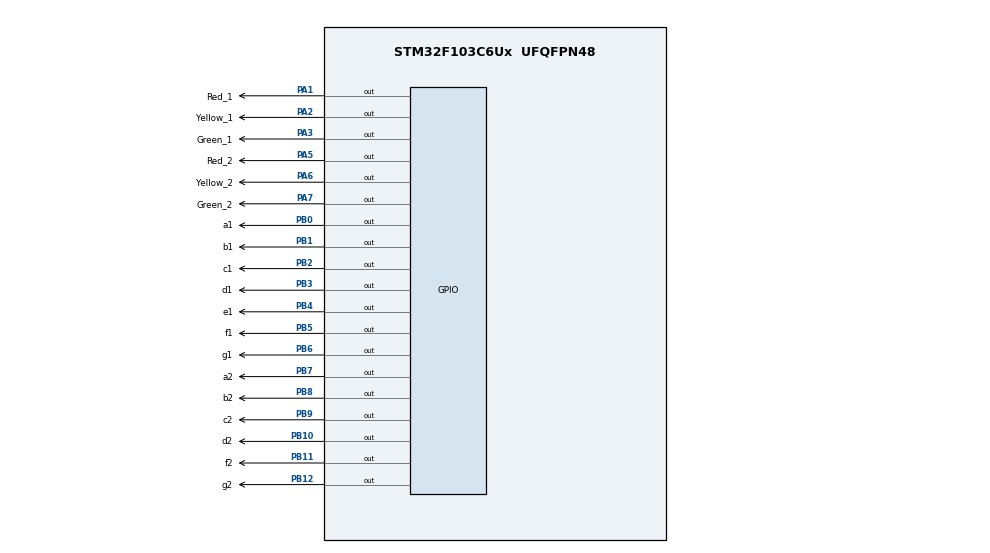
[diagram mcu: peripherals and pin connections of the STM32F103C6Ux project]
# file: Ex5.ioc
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Mcu.Family=STM32F1
Mcu.Name=STM32F103C6Ux
Mcu.Package=UFQFPN48
NVIC.PriorityGroup=NVIC_PRIORITYGROUP_4
PA1.GPIO_Label=Red_1
PA1.GPIO_ModeDefaultOutputPP=GPIO_MODE_OUTPUT_PP
PA1.PinState=GPIO_PIN_SET
PA1.Signal=GPIO_Output
PA13.Mode=Serial_Wire
PA13.Signal=SYS_JTMS-SWDIO
PA14.Mode=Serial_Wire
PA14.Signal=SYS_JTCK-SWCLK
PA2.GPIO_Label=Yellow_1
PA2.GPIO_ModeDefaultOutputPP=GPIO_MODE_OUTPUT_PP
PA2.PinState=GPIO_PIN_SET
PA2.Signal=GPIO_Output
PA3.GPIO_Label=Green_1
PA3.GPIO_ModeDefaultOutputPP=GPIO_MODE_OUTPUT_PP
PA3.PinState=GPIO_PIN_SET
PA3.Signal=GPIO_Output
PA5.GPIO_Label=Red_2
PA5.GPIO_ModeDefaultOutputPP=GPIO_MODE_OUTPUT_PP
PA5.PinState=GPIO_PIN_SET
PA5.Signal=GPIO_Output
PA6.GPIO_Label=Yellow_2
PA6.GPIO_ModeDefaultOutputPP=GPIO_MODE_OUTPUT_PP
PA6.PinState=GPIO_PIN_SET
PA6.Signal=GPIO_Output
PA7.GPIO_Label=Green_2
PA7.GPIO_ModeDefaultOutputPP=GPIO_MODE_OUTPUT_PP
PA7.PinState=GPIO_PIN_SET
PA7.Signal=GPIO_Output
PB0.GPIO_Label=a1
PB0.PinState=GPIO_PIN_SET
PB0.Signal=GPIO_Output
PB1.GPIO_Label=b1
PB1.PinState=GPIO_PIN_SET
PB1.Signal=GPIO_Output
PB10.GPIO_Label=d2
PB10.PinState=GPIO_PIN_SET
PB10.Signal=GPIO_Output
PB11.GPIO_Label=f2
PB11.PinState=GPIO_PIN_SET
PB11.Signal=GPIO_Output
PB12.GPIO_Label=g2
PB12.PinState=GPIO_PIN_SET
PB12.Signal=GPIO_Output
PB2.GPIO_Label=c1
PB2.PinState=GPIO_PIN_SET
PB2.Signal=GPIO_Output
PB3.GPIO_Label=d1
PB3.PinState=GPIO_PIN_SET
PB3.Signal=GPIO_Output
PB4.GPIO_Label=e1
PB4.PinState=GPIO_PIN_SET
PB4.Signal=GPIO_Output
PB5.GPIO_Label=f1
PB5.PinState=GPIO_PIN_SET
PB5.Signal=GPIO_Output
PB6.GPIO_Label=g1
PB6.PinState=GPIO_PIN_SET
PB6.Signal=GPIO_Output
PB7.GPIO_Label=a2
PB7.PinState=GPIO_PIN_SET
PB7.Signal=GPIO_Output
PB8.GPIO_Label=b2
PB8.PinState=GPIO_PIN_SET
PB8.Signal=GPIO_Output
PB9.GPIO_Label=c2
PB9.PinState=GPIO_PIN_SET
PB9.Signal=GPIO_Output
ProjectManager.HeapSize=0x200
ProjectManager.StackSize=0x400
ProjectManager.TargetToolchain=STM32CubeIDE
RCC.APB1Freq_Value=8000000
RCC.APB2Freq_Value=8000000
board=custom

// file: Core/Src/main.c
/* USER CODE BEGIN Header */
/**
  ******************************************************************************
  * @file           : main.c
  * @brief          : Main program body
  ******************************************************************************
  * @attention
  *
  * Copyright (c) 2026 STMicroelectronics.
  * All rights reserved.
  *
  * This software is licensed under terms that can be found in the LICENSE file
  * in the root directory of this software component.
  * If no LICENSE file comes with this software, it is provided AS-IS.
  *
  ******************************************************************************
  */
/* USER CODE END Header */
#include "main.h"

/* USER CODE BEGIN PV */
int count = 0;
int timer_1 = 0;
int timer_2 = 0;
/* USER CODE END PV */

void SystemClock_Config(void);
static void MX_GPIO_Init(void);

/* USER CODE BEGIN 0 */

// Mã 7 đoạn Anode chung (0: BẬT, 1: TẮT)
uint8_t seg_code[10] = {
    0x40, // 0
    0x79, // 1
    0x24, // 2
    0x30, // 3
    0x19, // 4
    0x12, // 5
    0x02, // 6
    0x78, // 7
    0x00, // 8
    0x10  // 9
};

void display7SEG_1(int num) {
    if (num >= 0 && num <= 9) {
        uint8_t code = seg_code[num];
        HAL_GPIO_WritePin(a1_GPIO_Port, a1_Pin, (code & 0x01) ? GPIO_PIN_SET : GPIO_PIN_RESET);
        HAL_GPIO_WritePin(b1_GPIO_Port, b1_Pin, (code & 0x02) ? GPIO_PIN_SET : GPIO_PIN_RESET);
        HAL_GPIO_WritePin(c1_GPIO_Port, c1_Pin, (code & 0x04) ? GPIO_PIN_SET : GPIO_PIN_RESET);
        HAL_GPIO_WritePin(d1_GPIO_Port, d1_Pin, (code & 0x08) ? GPIO_PIN_SET : GPIO_PIN_RESET);
        HAL_GPIO_WritePin(e1_GPIO_Port, e1_Pin, (code & 0x10) ? GPIO_PIN_SET : GPIO_PIN_RESET);
        HAL_GPIO_WritePin(f1_GPIO_Port, f1_Pin, (code & 0x20) ? GPIO_PIN_SET : GPIO_PIN_RESET);
        HAL_GPIO_WritePin(g1_GPIO_Port, g1_Pin, (code & 0x40) ? GPIO_PIN_SET : GPIO_PIN_RESET);
    }
}

void display7SEG_2(int num) {
    if (num >= 0 && num <= 9) {
        uint8_t code = seg_code[num];
        HAL_GPIO_WritePin(a2_GPIO_Port, a2_Pin, (code & 0x01) ? GPIO_PIN_SET : GPIO_PIN_RESET);
        HAL_GPIO_WritePin(b2_GPIO_Port, b2_Pin, (code & 0x02) ? GPIO_PIN_SET : GPIO_PIN_RESET);
        HAL_GPIO_WritePin(c2_GPIO_Port, c2_Pin, (code & 0x04) ? GPIO_PIN_SET : GPIO_PIN_RESET);
        HAL_GPIO_WritePin(d2_GPIO_Port, d2_Pin, (code & 0x08) ? GPIO_PIN_SET : GPIO_PIN_RESET);
        HAL_GPIO_WritePin(e2_GPIO_Port, e2_Pin, (code & 0x10) ? GPIO_PIN_SET : GPIO_PIN_RESET);
        HAL_GPIO_WritePin(f2_GPIO_Port, f2_Pin, (code & 0x20) ? GPIO_PIN_SET : GPIO_PIN_RESET);
        HAL_GPIO_WritePin(g2_GPIO_Port, g2_Pin, (code & 0x40) ? GPIO_PIN_SET : GPIO_PIN_RESET);
    }
}
/* USER CODE END 0 */

int main(void)
{

  /* MCU Configuration--------------------------------------------------------*/

  /* Reset of all peripherals, Initializes the Flash interface and the Systick. */
  HAL_Init();

  /* Configure the system clock */
  SystemClock_Config();

  /* Initialize all configured peripherals */
  MX_GPIO_Init();

  /* Infinite loop */
  /* USER CODE BEGIN WHILE */
  while (1)
  {
      if (count < 3)
      {
        // [0s, 1s, 2s]: Hướng 1 ĐỎ | Hướng 2 XANH
        HAL_GPIO_WritePin(Red_1_GPIO_Port, Red_1_Pin, GPIO_PIN_RESET);
        HAL_GPIO_WritePin(Yellow_1_GPIO_Port, Yellow_1_Pin, GPIO_PIN_SET);
        HAL_GPIO_WritePin(Green_1_GPIO_Port, Green_1_Pin, GPIO_PIN_SET);

        HAL_GPIO_WritePin(Red_2_GPIO_Port, Red_2_Pin, GPIO_PIN_SET);
        HAL_GPIO_WritePin(Yellow_2_GPIO_Port, Yellow_2_Pin, GPIO_PIN_SET);
        HAL_GPIO_WritePin(Green_2_GPIO_Port, Green_2_Pin, GPIO_PIN_RESET);

        timer_1 = 5 - count;
        timer_2 = 3 - count;
      }
      else if (count < 5)
      {
        // [3s, 4s]: Hướng 1 ĐỎ | Hướng 2 VÀNG
        HAL_GPIO_WritePin(Red_1_GPIO_Port, Red_1_Pin, GPIO_PIN_RESET);
        HAL_GPIO_WritePin(Yellow_1_GPIO_Port, Yellow_1_Pin, GPIO_PIN_SET);
        HAL_GPIO_WritePin(Green_1_GPIO_Port, Green_1_Pin, GPIO_PIN_SET);

        HAL_GPIO_WritePin(Red_2_GPIO_Port, Red_2_Pin, GPIO_PIN_SET);
        HAL_GPIO_WritePin(Yellow_2_GPIO_Port, Yellow_2_Pin, GPIO_PIN_RESET);
        HAL_GPIO_WritePin(Green_2_GPIO_Port, Green_2_Pin, GPIO_PIN_SET);

        timer_1 = 5 - count;
        timer_2 = 5 - count;
      }
      else if (count < 8)
      {
        // [5s, 6s, 7s]: Hướng 1 XANH | Hướng 2 ĐỎ
        HAL_GPIO_WritePin(Red_1_GPIO_Port, Red_1_Pin, GPIO_PIN_SET);
        HAL_GPIO_WritePin(Yellow_1_GPIO_Port, Yellow_1_Pin, GPIO_PIN_SET);
        HAL_GPIO_WritePin(Green_1_GPIO_Port, Green_1_Pin, GPIO_PIN_RESET);

        HAL_GPIO_WritePin(Red_2_GPIO_Port, Red_2_Pin, GPIO_PIN_RESET);
        HAL_GPIO_WritePin(Yellow_2_GPIO_Port, Yellow_2_Pin, GPIO_PIN_SET);
        HAL_GPIO_WritePin(Green_2_GPIO_Port, Green_2_Pin, GPIO_PIN_SET);

        timer_1 = 8 - count;
        timer_2 = 10 - count;
      }
      else
      {
        // [8s, 9s]: Hướng 1 VÀNG | Hướng 2 ĐỎ
        HAL_GPIO_WritePin(Red_1_GPIO_Port, Red_1_Pin, GPIO_PIN_SET);
        HAL_GPIO_WritePin(Yellow_1_GPIO_Port, Yellow_1_Pin, GPIO_PIN_RESET);
        HAL_GPIO_WritePin(Green_1_GPIO_Port, Green_1_Pin, GPIO_PIN_SET);

        HAL_GPIO_WritePin(Red_2_GPIO_Port, Red_2_Pin, GPIO_PIN_RESET);
        HAL_GPIO_WritePin(Yellow_2_GPIO_Port, Yellow_2_Pin, GPIO_PIN_SET);
        HAL_GPIO_WritePin(Green_2_GPIO_Port, Green_2_Pin, GPIO_PIN_SET);

        timer_1 = 10 - count;
        timer_2 = 10 - count;
      }

      display7SEG_1(timer_1);
      display7SEG_2(timer_2);

      HAL_Delay(1000);

      count++;
      if (count >= 10)
      {
        count = 0;
      }

    /* USER CODE END WHILE */
  }
}

void SystemClock_Config(void)
{
  RCC_OscInitTypeDef RCC_OscInitStruct = {0};
  RCC_ClkInitTypeDef RCC_ClkInitStruct = {0};

  /** Initializes the RCC Oscillators according to the specified parameters
  * in the RCC_OscInitTypeDef structure.
  */
  RCC_OscInitStruct.OscillatorType = RCC_OSCILLATORTYPE_HSI;
  RCC_OscInitStruct.HSIState = RCC_HSI_ON;
  RCC_OscInitStruct.HSICalibrationValue = RCC_HSICALIBRATION_DEFAULT;
  RCC_OscInitStruct.PLL.PLLState = RCC_PLL_NONE;
  if (HAL_RCC_OscConfig(&RCC_OscInitStruct) != HAL_OK)
  {
    Error_Handler();
  }

  /** Initializes the CPU, AHB and APB buses clocks
  */
  RCC_ClkInitStruct.ClockType = RCC_CLOCKTYPE_HCLK|RCC_CLOCKTYPE_SYSCLK
                              |RCC_CLOCKTYPE_PCLK1|RCC_CLOCKTYPE_PCLK2;
  RCC_ClkInitStruct.SYSCLKSource = RCC_SYSCLKSOURCE_HSI;
  RCC_ClkInitStruct.AHBCLKDivider = RCC_SYSCLK_DIV1;
  RCC_ClkInitStruct.APB1CLKDivider = RCC_HCLK_DIV1;
  RCC_ClkInitStruct.APB2CLKDivider = RCC_HCLK_DIV1;

  if (HAL_RCC_ClockConfig(&RCC_ClkInitStruct, FLASH_LATENCY_0) != HAL_OK)
  {
    Error_Handler();
  }
}

static void MX_GPIO_Init(void)
{
  GPIO_InitTypeDef GPIO_InitStruct = {0};

  /* GPIO Ports Clock Enable */
  __HAL_RCC_GPIOA_CLK_ENABLE();
  __HAL_RCC_GPIOB_CLK_ENABLE();

  /*Configure GPIO pin Output Level */
  HAL_GPIO_WritePin(GPIOA, Red_1_Pin|Yellow_1_Pin|Green_1_Pin|Red_2_Pin
                          |Yellow_2_Pin|Green_2_Pin, GPIO_PIN_SET);

  /*Configure GPIO pin Output Level */
  HAL_GPIO_WritePin(GPIOB, a1_Pin|b1_Pin|c1_Pin|d1_Pin|e1_Pin|f1_Pin|g1_Pin
                          |a2_Pin|b2_Pin|c2_Pin|d2_Pin|e2_Pin|f2_Pin|g2_Pin, GPIO_PIN_SET);

  /*Configure GPIO pins : Red_1_Pin Yellow_1_Pin Green_1_Pin Red_2_Pin
                           Yellow_2_Pin Green_2_Pin */
  GPIO_InitStruct.Pin = Red_1_Pin|Yellow_1_Pin|Green_1_Pin|Red_2_Pin
                          |Yellow_2_Pin|Green_2_Pin;
  GPIO_InitStruct.Mode = GPIO_MODE_OUTPUT_PP;
  GPIO_InitStruct.Pull = GPIO_NOPULL;
  GPIO_InitStruct.Speed = GPIO_SPEED_FREQ_LOW;
  HAL_GPIO_Init(GPIOA, &GPIO_InitStruct);

  /*Configure GPIO pins : a1_Pin b1_Pin c1_Pin d1_Pin e1_Pin f1_Pin g1_Pin
                           a2_Pin b2_Pin c2_Pin d2_Pin e2_Pin f2_Pin g2_Pin */
  GPIO_InitStruct.Pin = a1_Pin|b1_Pin|c1_Pin|d1_Pin|e1_Pin|f1_Pin|g1_Pin
                          |a2_Pin|b2_Pin|c2_Pin|d2_Pin|e2_Pin|f2_Pin|g2_Pin;
  GPIO_InitStruct.Mode = GPIO_MODE_OUTPUT_PP;
  GPIO_InitStruct.Pull = GPIO_NOPULL;
  GPIO_InitStruct.Speed = GPIO_SPEED_FREQ_LOW;
  HAL_GPIO_Init(GPIOB, &GPIO_InitStruct);

}

void Error_Handler(void)
{
  __disable_irq();
  while (1)
  {
  }
}
